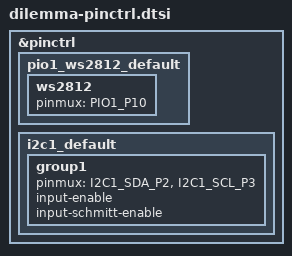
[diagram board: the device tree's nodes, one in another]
&pinctrl {
    pio1_ws2812_default: pio1_ws2812_default {
        ws2812 {
            pinmux = <PIO1_P10>;
        };
    };

    i2c1_default: i2c1_default {
        group1 {
            pinmux = <I2C1_SDA_P2>, <I2C1_SCL_P3>; // vik SDA / vik SCL
            input-enable;
            input-schmitt-enable;
        };
    };
};
